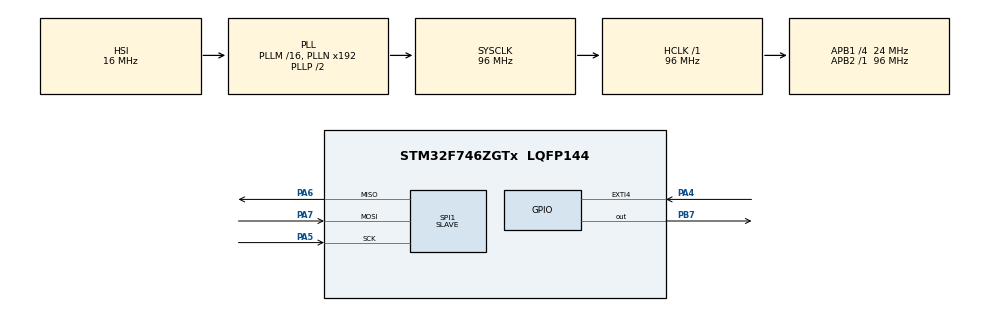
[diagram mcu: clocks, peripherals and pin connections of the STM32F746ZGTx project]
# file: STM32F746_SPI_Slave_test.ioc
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Mcu.Family=STM32F7
Dma.SPI1_TX.1.Priority=DMA_PRIORITY_MEDIUM
PA6.Mode=Full_Duplex_Slave
RCC.CortexFreq_Value=96000000
SPI1.VirtualType=VM_SLAVE
Dma.SPI1_TX.1.FIFOMode=DMA_FIFOMODE_DISABLE
Dma.SPI1_TX.1.PeriphInc=DMA_PINC_DISABLE
RCC.SYSCLKSource=RCC_SYSCLKSOURCE_PLLCLK
ProjectManager.StackSize=0x400
SPI1.CLKPolarity=SPI_POLARITY_LOW
Dma.SPI1_RX.0.Direction=DMA_PERIPH_TO_MEMORY
SPI1.Direction=SPI_DIRECTION_2LINES
RCC.HCLKFreq_Value=96000000
RCC.APB2TimFreq_Value=96000000
NVIC.DMA2_Stream0_IRQn=true\:0\:0\:false\:false\:true\:false\:true
PD8.Signal=USART3_TX
RCC.AHBFreq_Value=96000000
Dma.SPI1_TX.1.PeriphDataAlignment=DMA_PDATAALIGN_BYTE
RCC.HSE_VALUE=25000000
PA4.GPIO_PuPd=GPIO_PULLUP
Dma.SPI1_RX.0.PeriphInc=DMA_PINC_DISABLE
Dma.SPI1_TX.1.Mode=DMA_NORMAL
SPI1.DataSize=SPI_DATASIZE_8BIT
PB7.Signal=GPIO_Output
SPI1.FirstBit=SPI_FIRSTBIT_MSB
Mcu.Package=LQFP144
PA6.Signal=SPI1_MISO
Dma.Request1=SPI1_TX
RCC.APB1TimFreq_Value=48000000
PA6.GPIO_Speed=GPIO_SPEED_FREQ_VERY_HIGH
Dma.Request0=SPI1_RX
Dma.SPI1_TX.1.Instance=DMA2_Stream3
PA5.Mode=Full_Duplex_Slave
NVIC.EXTI4_IRQn=true\:0\:0\:false\:false\:true\:true\:true
Dma.SPI1_TX.1.MemInc=DMA_MINC_ENABLE
PA7.Mode=Full_Duplex_Slave
PD9.Signal=USART3_RX
SPI1.CLKPhase=SPI_PHASE_2EDGE
Dma.SPI1_RX.0.Mode=DMA_NORMAL
RCC.APB1CLKDivider=RCC_HCLK_DIV4
Dma.SPI1_TX.1.Direction=DMA_MEMORY_TO_PERIPH
PA13.Signal=SYS_JTMS-SWDIO
Dma.SPI1_RX.0.FIFOMode=DMA_FIFOMODE_DISABLE
Dma.SPI1_TX.1.MemDataAlignment=DMA_MDATAALIGN_BYTE
ProjectManager.TargetToolchain=STM32CubeIDE
PA4.GPIO_ModeDefaultEXTI=GPIO_MODE_IT_FALLING
RCC.USBFreq_Value=96000000
NVIC.DMA2_Stream3_IRQn=true\:0\:0\:false\:false\:true\:false\:true
RCC.LSE_VALUE=32768
PA5.Signal=SPI1_SCK
board=custom
RCC.VCOOutputFreq_Value=192000000
PA7.GPIO_Speed=GPIO_SPEED_FREQ_VERY_HIGH
NVIC.SPI1_IRQn=true\:0\:0\:false\:false\:true\:true\:true
RCC.APB2Freq_Value=96000000
SPI1.CRCCalculation=SPI_CRCCALCULATION_DISABLE
SPI1.Mode=SPI_MODE_SLAVE
Dma.SPI1_RX.0.Instance=DMA2_Stream0
Dma.SPI1_RX.0.PeriphDataAlignment=DMA_PDATAALIGN_BYTE
Dma.SPI1_RX.0.MemDataAlignment=DMA_MDATAALIGN_BYTE
Mcu.Name=STM32F746ZGTx
Dma.SPI1_RX.0.MemInc=DMA_MINC_ENABLE
PB3.Signal=SYS_JTDO-SWO
PA4.Signal=GPXTI4
RCC.SYSCLKFreq_VALUE=96000000
PA14.Signal=SYS_JTCK-SWCLK
ProjectManager.HeapSize=0x200
Dma.SPI1_RX.0.Priority=DMA_PRIORITY_MEDIUM
RCC.HSI_VALUE=16000000
PA5.GPIO_Speed=GPIO_SPEED_FREQ_VERY_HIGH
NVIC.PriorityGroup=NVIC_PRIORITYGROUP_4
RCC.APB1Freq_Value=24000000
PA7.Signal=SPI1_MOSI

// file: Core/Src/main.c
/* USER CODE BEGIN Header */
/**
  ******************************************************************************
  * @file           : main.c
  * @brief          : Main program body
  ******************************************************************************
  * @attention
  *
  * <h2><center>&copy; Copyright (c) 2021 STMicroelectronics.
  * All rights reserved.</center></h2>
  *
  * This software component is licensed by ST under BSD 3-Clause license,
  * the "License"; You may not use this file except in compliance with the
  * License. You may obtain a copy of the License at:
  *                        opensource.org/licenses/BSD-3-Clause
  *
  ******************************************************************************
  */
/* USER CODE END Header */
#include "main.h"

/* USER CODE BEGIN Includes */
#include <stdio.h>
/* USER CODE END Includes */

SPI_HandleTypeDef hspi1;
DMA_HandleTypeDef hdma_spi1_rx;
DMA_HandleTypeDef hdma_spi1_tx;

void SystemClock_Config(void);
static void MX_GPIO_Init(void);
static void MX_DMA_Init(void);
static void MX_SPI1_Init(void);

/* USER CODE BEGIN 0 */
uint8_t aRxBuffer[14]={0};
uint8_t aTxBuffer[14]= {0x58, 0x59, 0x60, 0x61, 0x62};

void HAL_GPIO_EXTI_Callback(uint16_t GPIO_Pin)
{
	HAL_GPIO_TogglePin(GPIOB, GPIO_PIN_7);
	if(GPIO_Pin == GPIO_PIN_4 ){
		//uint8_t counter = 0;
		if(!HAL_GPIO_ReadPin(GPIOC, GPIO_PIN_4)){
			//HAL_SPI_Transmit(&hspi1, &aTxBuffer[counter], 1, 10);
			//HAL_SPI_Receive(&hspi1, &aRxBuffer[counter], 1, 10);
			//counter++;
			//HAL_SPI_Transmit(&hspi1, aTxBuffer, 3, 100);
			//HAL_SPI_Receive(&hspi1, aRxBuffer, 11, 100);
			//HAL_SPI_TransmitReceive(&hspi1, aTxBuffer, aRxBuffer, 14, 200);
			HAL_SPI_TransmitReceive_DMA(&hspi1, aTxBuffer, aRxBuffer, 7);
		}
	}
}

/* USER CODE END 0 */

int main(void)
{

  /* MCU Configuration--------------------------------------------------------*/

  /* Reset of all peripherals, Initializes the Flash interface and the Systick. */
  HAL_Init();

  /* Configure the system clock */
  SystemClock_Config();

  /* Initialize all configured peripherals */
  MX_GPIO_Init();
  MX_DMA_Init();
  MX_SPI1_Init();

  /* Infinite loop */
  while (1)
  {

  }
}

void SystemClock_Config(void)
{
  RCC_OscInitTypeDef RCC_OscInitStruct = {0};
  RCC_ClkInitTypeDef RCC_ClkInitStruct = {0};

  /** Configure the main internal regulator output voltage
  */
  __HAL_RCC_PWR_CLK_ENABLE();
  __HAL_PWR_VOLTAGESCALING_CONFIG(PWR_REGULATOR_VOLTAGE_SCALE3);
  /** Initializes the RCC Oscillators according to the specified parameters
  * in the RCC_OscInitTypeDef structure.
  */
  RCC_OscInitStruct.OscillatorType = RCC_OSCILLATORTYPE_HSI;
  RCC_OscInitStruct.HSIState = RCC_HSI_ON;
  RCC_OscInitStruct.HSICalibrationValue = RCC_HSICALIBRATION_DEFAULT;
  RCC_OscInitStruct.PLL.PLLState = RCC_PLL_ON;
  RCC_OscInitStruct.PLL.PLLSource = RCC_PLLSOURCE_HSI;
  RCC_OscInitStruct.PLL.PLLM = 16;
  RCC_OscInitStruct.PLL.PLLN = 192;
  RCC_OscInitStruct.PLL.PLLP = RCC_PLLP_DIV2;
  RCC_OscInitStruct.PLL.PLLQ = 2;
  if (HAL_RCC_OscConfig(&RCC_OscInitStruct) != HAL_OK)
  {
    Error_Handler();
  }
  /** Activate the Over-Drive mode
  */
  if (HAL_PWREx_EnableOverDrive() != HAL_OK)
  {
    Error_Handler();
  }
  /** Initializes the CPU, AHB and APB buses clocks
  */
  RCC_ClkInitStruct.ClockType = RCC_CLOCKTYPE_HCLK|RCC_CLOCKTYPE_SYSCLK
                              |RCC_CLOCKTYPE_PCLK1|RCC_CLOCKTYPE_PCLK2;
  RCC_ClkInitStruct.SYSCLKSource = RCC_SYSCLKSOURCE_PLLCLK;
  RCC_ClkInitStruct.AHBCLKDivider = RCC_SYSCLK_DIV1;
  RCC_ClkInitStruct.APB1CLKDivider = RCC_HCLK_DIV4;
  RCC_ClkInitStruct.APB2CLKDivider = RCC_HCLK_DIV1;

  if (HAL_RCC_ClockConfig(&RCC_ClkInitStruct, FLASH_LATENCY_3) != HAL_OK)
  {
    Error_Handler();
  }
}

static void MX_SPI1_Init(void)
{

  /* SPI1 parameter configuration*/
  hspi1.Instance = SPI1;
  hspi1.Init.Mode = SPI_MODE_SLAVE;
  hspi1.Init.Direction = SPI_DIRECTION_2LINES;
  hspi1.Init.DataSize = SPI_DATASIZE_8BIT;
  hspi1.Init.CLKPolarity = SPI_POLARITY_LOW;
  hspi1.Init.CLKPhase = SPI_PHASE_2EDGE;
  hspi1.Init.NSS = SPI_NSS_SOFT;
  hspi1.Init.FirstBit = SPI_FIRSTBIT_MSB;
  hspi1.Init.TIMode = SPI_TIMODE_DISABLE;
  hspi1.Init.CRCCalculation = SPI_CRCCALCULATION_DISABLE;
  hspi1.Init.CRCPolynomial = 7;
  hspi1.Init.CRCLength = SPI_CRC_LENGTH_DATASIZE;
  hspi1.Init.NSSPMode = SPI_NSS_PULSE_DISABLE;
  if (HAL_SPI_Init(&hspi1) != HAL_OK)
  {
    Error_Handler();
  }

}

static void MX_DMA_Init(void)
{

  /* DMA controller clock enable */
  __HAL_RCC_DMA2_CLK_ENABLE();

  /* DMA interrupt init */
  /* DMA2_Stream0_IRQn interrupt configuration */
  HAL_NVIC_SetPriority(DMA2_Stream0_IRQn, 0, 0);
  HAL_NVIC_EnableIRQ(DMA2_Stream0_IRQn);
  /* DMA2_Stream3_IRQn interrupt configuration */
  HAL_NVIC_SetPriority(DMA2_Stream3_IRQn, 0, 0);
  HAL_NVIC_EnableIRQ(DMA2_Stream3_IRQn);

}

static void MX_GPIO_Init(void)
{
  GPIO_InitTypeDef GPIO_InitStruct = {0};

  /* GPIO Ports Clock Enable */
  __HAL_RCC_GPIOA_CLK_ENABLE();
  __HAL_RCC_GPIOD_CLK_ENABLE();
  __HAL_RCC_GPIOB_CLK_ENABLE();

  /*Configure GPIO pin Output Level */
  HAL_GPIO_WritePin(GPIOB, GPIO_PIN_7, GPIO_PIN_RESET);

  /*Configure GPIO pin : PA4 */
  GPIO_InitStruct.Pin = GPIO_PIN_4;
  GPIO_InitStruct.Mode = GPIO_MODE_IT_FALLING;
  GPIO_InitStruct.Pull = GPIO_PULLUP;
  HAL_GPIO_Init(GPIOA, &GPIO_InitStruct);

  /*Configure GPIO pins : PD8 PD9 */
  GPIO_InitStruct.Pin = GPIO_PIN_8|GPIO_PIN_9;
  GPIO_InitStruct.Mode = GPIO_MODE_AF_PP;
  GPIO_InitStruct.Pull = GPIO_NOPULL;
  GPIO_InitStruct.Speed = GPIO_SPEED_FREQ_VERY_HIGH;
  GPIO_InitStruct.Alternate = GPIO_AF7_USART3;
  HAL_GPIO_Init(GPIOD, &GPIO_InitStruct);

  /*Configure GPIO pin : PB7 */
  GPIO_InitStruct.Pin = GPIO_PIN_7;
  GPIO_InitStruct.Mode = GPIO_MODE_OUTPUT_PP;
  GPIO_InitStruct.Pull = GPIO_NOPULL;
  GPIO_InitStruct.Speed = GPIO_SPEED_FREQ_LOW;
  HAL_GPIO_Init(GPIOB, &GPIO_InitStruct);

  /* EXTI interrupt init*/
  HAL_NVIC_SetPriority(EXTI4_IRQn, 0, 0);
  HAL_NVIC_EnableIRQ(EXTI4_IRQn);

}

/* USER CODE BEGIN 4 */
int _write(int file, char *ptr, int len)
{
  int DataIdx;
  for(DataIdx=0; DataIdx<len; DataIdx++)
  {
    ITM_SendChar(*ptr++);
  }
  return len;
}

/* USER CODE END 4 */

void Error_Handler(void)
{
  __disable_irq();
  while (1)
  {
  }
}

/************************ (C) COPYRIGHT STMicroelectronics *****END OF FILE****/
